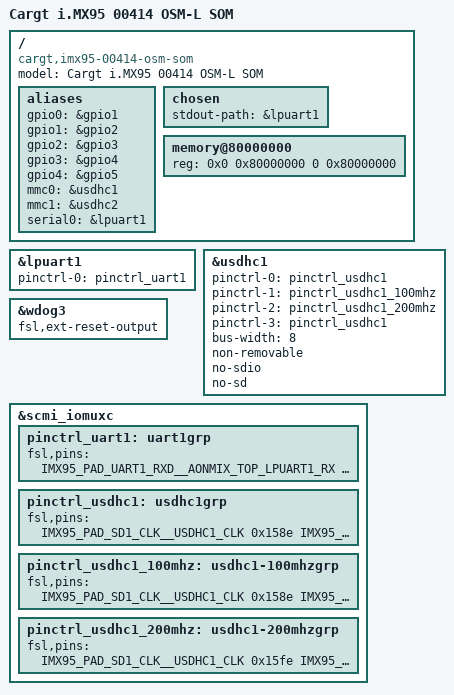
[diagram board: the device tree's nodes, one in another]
// SPDX-License-Identifier: (GPL-2.0+ OR MIT)
/*
 * Copyright 2024 NXP
 * Copyright 2026 Cargt
 *
 * Cargt i.MX 95 00414 OSM-L SOM (U-Boot). SOM-level hardware only.
 *
 * LPI2C1 (PMICs, RX8111 RTC, EEPROM) belongs to the System Manager and is
 * not described here.
 */

/dts-v1/;

#include "../dts/upstream/src/arm64/freescale/imx95.dtsi"

/ {
	model = "Cargt i.MX95 00414 OSM-L SOM";
	compatible = "cargt,imx95-00414-osm-som", "fsl,imx95";

	aliases {
		gpio0 = &gpio1;
		gpio1 = &gpio2;
		gpio2 = &gpio3;
		gpio3 = &gpio4;
		gpio4 = &gpio5;
		mmc0 = &usdhc1;
		mmc1 = &usdhc2;
		serial0 = &lpuart1;
	};

	chosen {
		stdout-path = &lpuart1;
	};

	memory@80000000 {
		device_type = "memory";
		reg = <0x0 0x80000000 0 0x80000000>;
	};
};

&lpuart1 {
	/* OSM UART_CON (console) */
	pinctrl-names = "default";
	pinctrl-0 = <&pinctrl_uart1>;
	status = "okay";
};

&usdhc1 {
	pinctrl-names = "default", "state_100mhz", "state_200mhz", "sleep";
	pinctrl-0 = <&pinctrl_usdhc1>;
	pinctrl-1 = <&pinctrl_usdhc1_100mhz>;
	pinctrl-2 = <&pinctrl_usdhc1_200mhz>;
	pinctrl-3 = <&pinctrl_usdhc1>;
	bus-width = <8>;
	non-removable;
	no-sdio;
	no-sd;
	status = "okay";
};

&wdog3 {
	fsl,ext-reset-output;
	status = "okay";
};

&scmi_iomuxc {
	pinctrl_uart1: uart1grp {
		fsl,pins = <
			IMX95_PAD_UART1_RXD__AONMIX_TOP_LPUART1_RX		0x31e
			IMX95_PAD_UART1_TXD__AONMIX_TOP_LPUART1_TX		0x31e
		>;
	};

	pinctrl_usdhc1: usdhc1grp {
		fsl,pins = <
			IMX95_PAD_SD1_CLK__USDHC1_CLK			0x158e
			IMX95_PAD_SD1_CMD__USDHC1_CMD			0x138e
			IMX95_PAD_SD1_DATA0__USDHC1_DATA0		0x138e
			IMX95_PAD_SD1_DATA1__USDHC1_DATA1		0x138e
			IMX95_PAD_SD1_DATA2__USDHC1_DATA2		0x138e
			IMX95_PAD_SD1_DATA3__USDHC1_DATA3		0x138e
			IMX95_PAD_SD1_DATA4__USDHC1_DATA4		0x138e
			IMX95_PAD_SD1_DATA5__USDHC1_DATA5		0x138e
			IMX95_PAD_SD1_DATA6__USDHC1_DATA6		0x138e
			IMX95_PAD_SD1_DATA7__USDHC1_DATA7		0x138e
			IMX95_PAD_SD1_STROBE__USDHC1_STROBE		0x158e
		>;
	};

	pinctrl_usdhc1_100mhz: usdhc1-100mhzgrp {
		fsl,pins = <
			IMX95_PAD_SD1_CLK__USDHC1_CLK			0x158e
			IMX95_PAD_SD1_CMD__USDHC1_CMD			0x138e
			IMX95_PAD_SD1_DATA0__USDHC1_DATA0		0x138e
			IMX95_PAD_SD1_DATA1__USDHC1_DATA1		0x138e
			IMX95_PAD_SD1_DATA2__USDHC1_DATA2		0x138e
			IMX95_PAD_SD1_DATA3__USDHC1_DATA3		0x138e
			IMX95_PAD_SD1_DATA4__USDHC1_DATA4		0x138e
			IMX95_PAD_SD1_DATA5__USDHC1_DATA5		0x138e
			IMX95_PAD_SD1_DATA6__USDHC1_DATA6		0x138e
			IMX95_PAD_SD1_DATA7__USDHC1_DATA7		0x138e
			IMX95_PAD_SD1_STROBE__USDHC1_STROBE		0x158e
		>;
	};

	pinctrl_usdhc1_200mhz: usdhc1-200mhzgrp {
		fsl,pins = <
			IMX95_PAD_SD1_CLK__USDHC1_CLK			0x15fe
			IMX95_PAD_SD1_CMD__USDHC1_CMD			0x13fe
			IMX95_PAD_SD1_DATA0__USDHC1_DATA0		0x13fe
			IMX95_PAD_SD1_DATA1__USDHC1_DATA1		0x13fe
			IMX95_PAD_SD1_DATA2__USDHC1_DATA2		0x13fe
			IMX95_PAD_SD1_DATA3__USDHC1_DATA3		0x13fe
			IMX95_PAD_SD1_DATA4__USDHC1_DATA4		0x13fe
			IMX95_PAD_SD1_DATA5__USDHC1_DATA5		0x13fe
			IMX95_PAD_SD1_DATA6__USDHC1_DATA6		0x13fe
			IMX95_PAD_SD1_DATA7__USDHC1_DATA7		0x13fe
			IMX95_PAD_SD1_STROBE__USDHC1_STROBE		0x15fe
		>;
	};
};
